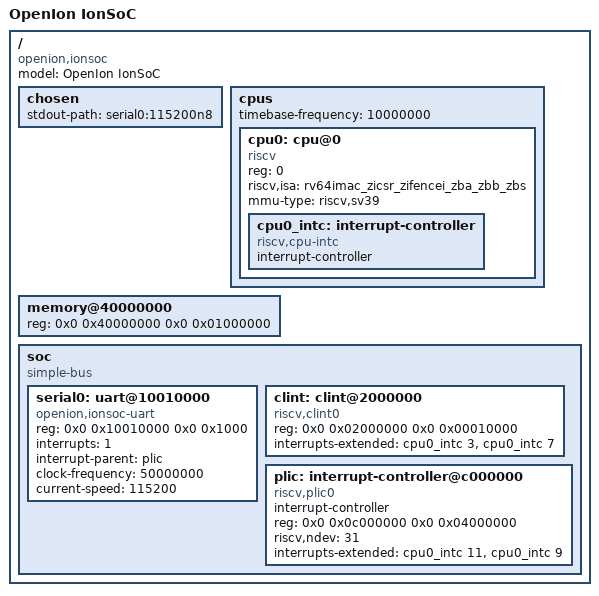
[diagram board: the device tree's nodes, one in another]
/dts-v1/;

/ {
    #address-cells = <2>;
    #size-cells = <2>;
    compatible = "openion,ionsoc";
    model = "OpenIon IonSoC";

    chosen {
        stdout-path = "serial0:115200n8";
    };

    cpus {
        #address-cells = <1>;
        #size-cells = <0>;
        timebase-frequency = <10000000>;

        cpu0: cpu@0 {
            device_type = "cpu";
            reg = <0>;
            status = "okay";
            compatible = "riscv";
            riscv,isa = "rv64imac_zicsr_zifencei_zba_zbb_zbs";
            mmu-type = "riscv,sv39";

            cpu0_intc: interrupt-controller {
                #interrupt-cells = <1>;
                interrupt-controller;
                compatible = "riscv,cpu-intc";
            };
        };
    };

    memory@40000000 {
        device_type = "memory";
        reg = <0x0 0x40000000 0x0 0x01000000>;
    };

    soc {
        #address-cells = <2>;
        #size-cells = <2>;
        compatible = "simple-bus";
        ranges;

        serial0: uart@10010000 {
            compatible = "openion,ionsoc-uart";
            reg = <0x0 0x10010000 0x0 0x1000>;
            interrupts = <1>;
            interrupt-parent = <&plic>;
            clock-frequency = <50000000>;
            current-speed = <115200>;
            status = "okay";
        };

        clint: clint@2000000 {
            compatible = "riscv,clint0";
            reg = <0x0 0x02000000 0x0 0x00010000>;
            interrupts-extended = <&cpu0_intc 3>, <&cpu0_intc 7>;
        };

        plic: interrupt-controller@c000000 {
            #address-cells = <0>;
            #interrupt-cells = <1>;
            compatible = "riscv,plic0";
            interrupt-controller;
            reg = <0x0 0x0c000000 0x0 0x04000000>;
            riscv,ndev = <31>;
            interrupts-extended = <&cpu0_intc 11>, <&cpu0_intc 9>;
        };
    };
};
